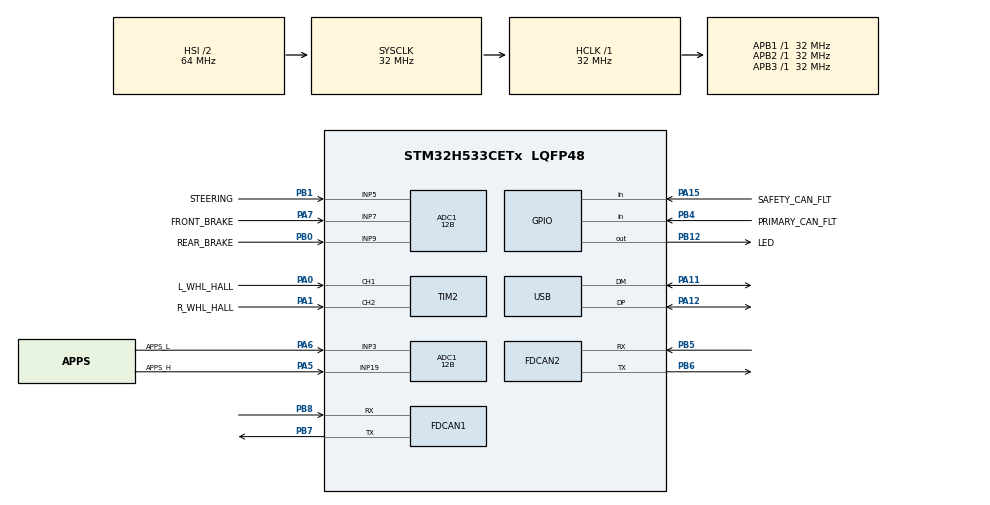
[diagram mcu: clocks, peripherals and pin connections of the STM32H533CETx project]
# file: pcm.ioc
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ADC1.Channel-1\#ChannelRegularConversion=ADC_CHANNEL_19
ADC1.Channel-2\#ChannelRegularConversion=ADC_CHANNEL_3
ADC1.Channel-3\#ChannelRegularConversion=ADC_CHANNEL_7
ADC1.Channel-4\#ChannelRegularConversion=ADC_CHANNEL_9
ADC1.Channel-5\#ChannelRegularConversion=ADC_CHANNEL_5
ADC1.DMAContinuousRequests=ENABLE
ADC1.MonitoredBy-1\#ChannelRegularConversion=__NULL
ADC1.MonitoredBy-2\#ChannelRegularConversion=__NULL
ADC1.MonitoredBy-3\#ChannelRegularConversion=__NULL
ADC1.MonitoredBy-4\#ChannelRegularConversion=__NULL
ADC1.MonitoredBy-5\#ChannelRegularConversion=__NULL
ADC1.NbrOfConversion=5
ADC1.NbrOfConversionFlag=1
ADC1.OffsetNumber-1\#ChannelRegularConversion=ADC_OFFSET_NONE
ADC1.OffsetNumber-2\#ChannelRegularConversion=ADC_OFFSET_NONE
ADC1.OffsetNumber-3\#ChannelRegularConversion=ADC_OFFSET_NONE
ADC1.OffsetNumber-4\#ChannelRegularConversion=ADC_OFFSET_NONE
ADC1.OffsetNumber-5\#ChannelRegularConversion=ADC_OFFSET_NONE
ADC1.Overrun=ADC_OVR_DATA_OVERWRITTEN
ADC1.Rank-1\#ChannelRegularConversion=1
ADC1.Rank-2\#ChannelRegularConversion=2
ADC1.Rank-3\#ChannelRegularConversion=3
ADC1.Rank-4\#ChannelRegularConversion=4
ADC1.Rank-5\#ChannelRegularConversion=5
ADC1.Resolution=ADC_RESOLUTION_12B
ADC1.SamplingTime-1\#ChannelRegularConversion=ADC_SAMPLETIME_47CYCLES_5
ADC1.SamplingTime-2\#ChannelRegularConversion=ADC_SAMPLETIME_47CYCLES_5
ADC1.SamplingTime-3\#ChannelRegularConversion=ADC_SAMPLETIME_47CYCLES_5
ADC1.SamplingTime-4\#ChannelRegularConversion=ADC_SAMPLETIME_47CYCLES_5
ADC1.SamplingTime-5\#ChannelRegularConversion=ADC_SAMPLETIME_47CYCLES_5
ADC1.master=1
BOOTPATH.BootPathName=LEGACY
BOOTPATH.UserSelectedBootPath=LEGACY
CORTEX_M33_NS.Number-Cortex_Memory_Protection_Unit_Region0_OTP_RO_AREAS_Settings=MPU_REGION_NUMBER0
CORTEX_M33_NS.default_mode_Activation=1
CORTEX_M33_NS.userName=CORTEX_M33
FDCAN1.CalculateBaudRateNominal=500000
FDCAN1.CalculateTimeBitNominal=2000
FDCAN1.CalculateTimeQuantumNominal=666.6666666666666
FDCAN2.CalculateBaudRateNominal=500000
FDCAN2.CalculateTimeBitNominal=2000
FDCAN2.CalculateTimeQuantumNominal=666.6666666666666
GPDMA1.DESTDATAWIDTH_GPDMACH0=DMA_DEST_DATAWIDTH_HALFWORD
GPDMA1.DESTINC_GPDMACH0=DMA_DINC_INCREMENTED
GPDMA1.IPHANDLE_GPDMACH0-SIMPLEREQUEST_GPDMACH0=__NULL
GPDMA1.REQUEST_GPDMACH0=GPDMA1_REQUEST_ADC1
GPDMA1.SRCDATAWIDTH_GPDMACH0=DMA_SRC_DATAWIDTH_HALFWORD
Mcu.Family=STM32H5
Mcu.Name=STM32H533CETx
Mcu.Package=LQFP48
NVIC.GPDMA1_Channel0_IRQn=true\:0\:0\:false\:false\:true\:true\:false\:true\:true
NVIC.PriorityGroup=NVIC_PRIORITYGROUP_4
NVIC.TIM7_IRQn=true\:15\:0\:false\:false\:true\:false\:false\:true\:true
NVIC.TimeBase=TIM7_IRQn
NVIC.TimeBaseIP=TIM7
NVIC.USB_DRD_FS_IRQn=true\:0\:0\:false\:false\:true\:false\:true\:true\:true
PA0.GPIO_Label=L_WHL_HALL
PA0.Signal=S_TIM2_CH1
PA1.GPIO_Label=R_WHL_HALL
PA1.Signal=S_TIM2_CH2
PA11.Mode=Device
PA11.Signal=USB_DM
PA12.Mode=Device
PA12.Signal=USB_DP
PA13(JTMS/SWDIO).Mode=Trace_Asynchronous_SW
PA13(JTMS/SWDIO).Signal=DEBUG_JTMS-SWDIO
PA14(JTCK/SWCLK).Mode=Trace_Asynchronous_SW
PA14(JTCK/SWCLK).Signal=DEBUG_JTCK-SWCLK
PA15(JTDI).GPIO_Label=SAFETY_CAN_FLT
PA15(JTDI).Signal=GPIO_Input
PA5.GPIO_Label=APPS_H
PA5.Signal=ADCx_INP19
PA6.GPIO_Label=APPS_L
PA6.Signal=ADCx_INP3
PA7.GPIO_Label=FRONT_BRAKE
PA7.Signal=ADCx_INP7
PB0.GPIO_Label=REAR_BRAKE
PB0.Signal=ADCx_INP9
PB1.GPIO_Label=STEERING
PB1.Signal=ADCx_INP5
PB12.GPIO_Label=LED
PB12.Signal=GPIO_Output
PB3(JTDO/TRACESWO).Mode=Trace_Asynchronous_SW
PB3(JTDO/TRACESWO).Signal=DEBUG_JTDO-SWO
PB4(NJTRST).GPIO_Label=PRIMARY_CAN_FLT
PB4(NJTRST).Signal=GPIO_Input
PB5.Mode=FDCAN_Activate
PB5.Signal=FDCAN2_RX
PB6.Mode=FDCAN_Activate
PB6.Signal=FDCAN2_TX
PB7.Mode=FDCAN_Activate
PB7.Signal=FDCAN1_TX
PB8.Mode=FDCAN_Activate
PB8.Signal=FDCAN1_RX
PC14-OSC32_IN(OSC32_IN).Mode=LSE-External-Oscillator
PC14-OSC32_IN(OSC32_IN).Signal=RCC_OSC32_IN
PC15-OSC32_OUT(OSC32_OUT).Mode=LSE-External-Oscillator
PC15-OSC32_OUT(OSC32_OUT).Signal=RCC_OSC32_OUT
PH0-OSC_IN(PH0).Mode=HSE-External-Oscillator
PH0-OSC_IN(PH0).Signal=RCC_OSC_IN
PH1-OSC_OUT(PH1).Mode=HSE-External-Oscillator
PH1-OSC_OUT(PH1).Signal=RCC_OSC_OUT
ProjectManager.HeapSize=0x200
ProjectManager.StackSize=0x400
ProjectManager.TargetToolchain=CMake
RCC.ADCFreq_Value=32000000
RCC.AHBFreq_Value=32000000
RCC.APB1Freq_Value=32000000
RCC.APB1TimFreq_Value=32000000
RCC.APB2Freq_Value=32000000
RCC.APB2TimFreq_Value=32000000
RCC.APB3Freq_Value=32000000
RCC.CSI_VALUE=4000000
RCC.CortexFreq_Value=32000000
RCC.EPOD_VALUE=4000000
RCC.HCLKFreq_Value=32000000
RCC.HSE_VALUE=24000000
RCC.HSI48_VALUE=48000000
RCC.HSI_VALUE=64000000
RCC.LSIRC_VALUE=32000
RCC.SYSCLKFreq_VALUE=32000000
RCC.USBFreq_Value=48000000
RCC.VCOOutputFreq_Value=516000000
SH.ADCx_INP19.0=ADC1_INP19,IN19-Single-Ended
SH.ADCx_INP3.0=ADC1_INP3,IN3-Single-Ended
SH.ADCx_INP5.0=ADC1_INP5,IN5-Single-Ended
SH.ADCx_INP7.0=ADC1_INP7,IN7-Single-Ended
SH.ADCx_INP9.0=ADC1_INP9,IN9-Single-Ended
SH.S_TIM2_CH1.0=TIM2_CH1,Input_Capture1_from_TI1
SH.S_TIM2_CH2.0=TIM2_CH2,Input_Capture2_from_TI2
THREADX.TX_APP_GENERATE_INIT_CODE=true
THREADX.TX_APP_MEM_POOL_SIZE=65536
TIM2.Channel-Input_Capture1_from_TI1=TIM_CHANNEL_1
TIM2.Channel-Input_Capture2_from_TI2=TIM_CHANNEL_2
USB.VirtualMode=Device_Only
USBX.BSP.number=1
USBX.Core_System=1
USBX.USBD_CDCACM_EPIN_ADDR=2
USBX.USBD_CDCACM_EPOUT_ADDR=3
USBX.USBD_MANUFACTURER_STRING=IIT Motorsports
USBX.USBD_PRODUCT_STRING=Propulsion Control Module (PCM)
USBX.USBX_SYS_SIZE=10240
USBX.UX_APP_MEM_POOL_SIZE=20480
USBX.UX_DEVICE_CDC_ACM=1
USBX.UX_DEVICE_ENABLED_FS=1
USBX.UX_Device_Controller=1
USBX.UX_Device_CoreStack=1
USBX.UX_enabled_FS=1
USBX0.BSP.STBoard=false
USBX0.BSP.api=Unknown
USBX0.BSP.condition=\!DIE47A
USBX0.BSP.instance=USB
USBX0.BSP.ip=USB
USBX0.BSP.mode=Device_Only
USBX0.BSP.name=USB_Device
USBX0.BSP.solution=USB
VP_BOOTPATH_VS_BOOTPATH.Mode=BP_Activate
VP_CORTEX_M33_NS_VS_Hclk.Mode=Hclk_Mode
VP_GPDMA1_VS_GPDMACH0.Mode=SIMPLEREQUEST_GPDMACH0
VP_ICACHE_VS_ICACHE.Mode=DirectMappedCache
VP_MEMORYMAP_VS_MEMORYMAP.Mode=CurAppReg
VP_PWR_VS_LPOM.Mode=PowerOptimisation
VP_PWR_VS_SECSignals.Mode=Security/Privilege
VP_SYS_VS_tim7.Mode=TIM7
VP_THREADX_VS_RTOSJjThreadXJjCoreJjDefault.Mode=Core_Default
VP_USBX_Core_System.Mode=Core_System
VP_USBX_UX\ Device\ CDC\ ACM\ Class_FS.Mode=UX_Device_class_CDC_ACM_FS_HS
VP_USBX_UX\ Device\ Controller_FS.Mode=UX_Device_Controller_FS
VP_USBX_UX\ Device\ CoreStack_FS.Mode=UX_Device_CoreStack
board=custom

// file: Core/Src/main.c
/* USER CODE BEGIN Header */
/**
  ******************************************************************************
  * @file           : main.c
  * @brief          : Main program body
  ******************************************************************************
  * @attention
  *
  * Copyright (c) 2026 STMicroelectronics.
  * All rights reserved.
  *
  * This software is licensed under terms that can be found in the LICENSE file
  * in the root directory of this software component.
  * If no LICENSE file comes with this software, it is provided AS-IS.
  *
  ******************************************************************************
  */
/* USER CODE END Header */
#include "app_threadx.h"
#include "main.h"

/* USER CODE BEGIN Includes */
#include "pcm.h"
/* USER CODE END Includes */

ADC_HandleTypeDef hadc1;
DMA_HandleTypeDef handle_GPDMA1_Channel0;

FDCAN_HandleTypeDef hfdcan1;
FDCAN_HandleTypeDef hfdcan2;

TIM_HandleTypeDef htim2;

PCD_HandleTypeDef hpcd_USB_DRD_FS;

void SystemClock_Config(void);
static void MPU_Config(void);
static void MX_GPIO_Init(void);
static void MX_GPDMA1_Init(void);
static void MX_ADC1_Init(void);
static void MX_FDCAN1_Init(void);
static void MX_FDCAN2_Init(void);
static void MX_ICACHE_Init(void);
static void MX_TIM2_Init(void);

int main(void)
{

  /* MCU Configuration--------------------------------------------------------*/

  /* MPU Configuration--------------------------------------------------------*/
  MPU_Config();

  /* Reset of all peripherals, Initializes the Flash interface and the Systick. */
  HAL_Init();

  /* Configure the system clock */
  SystemClock_Config();

  /* Initialize all configured peripherals */
  MX_GPIO_Init();
  MX_GPDMA1_Init();
  MX_ADC1_Init();
  MX_FDCAN1_Init();
  MX_FDCAN2_Init();
  MX_ICACHE_Init();
  MX_TIM2_Init();
  /* USER CODE BEGIN 2 */
  pcm_init();
  /* USER CODE END 2 */

  MX_ThreadX_Init();

  /* We should never get here as control is now taken by the scheduler */

  /* Infinite loop */
  while (1)
  {

  }
}

void SystemClock_Config(void)
{
  RCC_OscInitTypeDef RCC_OscInitStruct = {0};
  RCC_ClkInitTypeDef RCC_ClkInitStruct = {0};

  /** Configure the main internal regulator output voltage
  */
  __HAL_PWR_VOLTAGESCALING_CONFIG(PWR_REGULATOR_VOLTAGE_SCALE3);

  while(!__HAL_PWR_GET_FLAG(PWR_FLAG_VOSRDY)) {}

  /** Initializes the RCC Oscillators according to the specified parameters
  * in the RCC_OscInitTypeDef structure.
  */
  RCC_OscInitStruct.OscillatorType = RCC_OSCILLATORTYPE_HSI48|RCC_OSCILLATORTYPE_HSI
                              |RCC_OSCILLATORTYPE_HSE;
  RCC_OscInitStruct.HSEState = RCC_HSE_ON;
  RCC_OscInitStruct.HSIState = RCC_HSI_ON;
  RCC_OscInitStruct.HSIDiv = RCC_HSI_DIV2;
  RCC_OscInitStruct.HSICalibrationValue = RCC_HSICALIBRATION_DEFAULT;
  RCC_OscInitStruct.HSI48State = RCC_HSI48_ON;
  RCC_OscInitStruct.PLL.PLLState = RCC_PLL_NONE;
  if (HAL_RCC_OscConfig(&RCC_OscInitStruct) != HAL_OK)
  {
    Error_Handler();
  }

  /** Initializes the CPU, AHB and APB buses clocks
  */
  RCC_ClkInitStruct.ClockType = RCC_CLOCKTYPE_HCLK|RCC_CLOCKTYPE_SYSCLK
                              |RCC_CLOCKTYPE_PCLK1|RCC_CLOCKTYPE_PCLK2
                              |RCC_CLOCKTYPE_PCLK3;
  RCC_ClkInitStruct.SYSCLKSource = RCC_SYSCLKSOURCE_HSI;
  RCC_ClkInitStruct.AHBCLKDivider = RCC_SYSCLK_DIV1;
  RCC_ClkInitStruct.APB1CLKDivider = RCC_HCLK_DIV1;
  RCC_ClkInitStruct.APB2CLKDivider = RCC_HCLK_DIV1;
  RCC_ClkInitStruct.APB3CLKDivider = RCC_HCLK_DIV1;

  if (HAL_RCC_ClockConfig(&RCC_ClkInitStruct, FLASH_LATENCY_1) != HAL_OK)
  {
    Error_Handler();
  }

  /** Configure the programming delay
  */
  __HAL_FLASH_SET_PROGRAM_DELAY(FLASH_PROGRAMMING_DELAY_0);
}

static void MX_ADC1_Init(void)
{

  ADC_ChannelConfTypeDef sConfig = {0};

  /** Common config
  */
  hadc1.Instance = ADC1;
  hadc1.Init.ClockPrescaler = ADC_CLOCK_ASYNC_DIV1;
  hadc1.Init.Resolution = ADC_RESOLUTION_12B;
  hadc1.Init.DataAlign = ADC_DATAALIGN_RIGHT;
  hadc1.Init.ScanConvMode = ADC_SCAN_ENABLE;
  hadc1.Init.EOCSelection = ADC_EOC_SINGLE_CONV;
  hadc1.Init.LowPowerAutoWait = DISABLE;
  hadc1.Init.ContinuousConvMode = DISABLE;
  hadc1.Init.NbrOfConversion = 5;
  hadc1.Init.DiscontinuousConvMode = DISABLE;
  hadc1.Init.ExternalTrigConv = ADC_SOFTWARE_START;
  hadc1.Init.ExternalTrigConvEdge = ADC_EXTERNALTRIGCONVEDGE_NONE;
  hadc1.Init.DMAContinuousRequests = ENABLE;
  hadc1.Init.SamplingMode = ADC_SAMPLING_MODE_NORMAL;
  hadc1.Init.Overrun = ADC_OVR_DATA_OVERWRITTEN;
  hadc1.Init.OversamplingMode = DISABLE;
  if (HAL_ADC_Init(&hadc1) != HAL_OK)
  {
    Error_Handler();
  }

  /** Configure Regular Channel
  */
  sConfig.Channel = ADC_CHANNEL_19;
  sConfig.Rank = ADC_REGULAR_RANK_1;
  sConfig.SamplingTime = ADC_SAMPLETIME_47CYCLES_5;
  sConfig.SingleDiff = ADC_SINGLE_ENDED;
  sConfig.OffsetNumber = ADC_OFFSET_NONE;
  sConfig.Offset = 0;
  if (HAL_ADC_ConfigChannel(&hadc1, &sConfig) != HAL_OK)
  {
    Error_Handler();
  }

  /** Configure Regular Channel
  */
  sConfig.Channel = ADC_CHANNEL_3;
  sConfig.Rank = ADC_REGULAR_RANK_2;
  if (HAL_ADC_ConfigChannel(&hadc1, &sConfig) != HAL_OK)
  {
    Error_Handler();
  }

  /** Configure Regular Channel
  */
  sConfig.Channel = ADC_CHANNEL_7;
  sConfig.Rank = ADC_REGULAR_RANK_3;
  if (HAL_ADC_ConfigChannel(&hadc1, &sConfig) != HAL_OK)
  {
    Error_Handler();
  }

  /** Configure Regular Channel
  */
  sConfig.Channel = ADC_CHANNEL_9;
  sConfig.Rank = ADC_REGULAR_RANK_4;
  if (HAL_ADC_ConfigChannel(&hadc1, &sConfig) != HAL_OK)
  {
    Error_Handler();
  }

  /** Configure Regular Channel
  */
  sConfig.Channel = ADC_CHANNEL_5;
  sConfig.Rank = ADC_REGULAR_RANK_5;
  if (HAL_ADC_ConfigChannel(&hadc1, &sConfig) != HAL_OK)
  {
    Error_Handler();
  }

}

static void MX_FDCAN1_Init(void)
{

  hfdcan1.Instance = FDCAN1;
  hfdcan1.Init.ClockDivider = FDCAN_CLOCK_DIV1;
  hfdcan1.Init.FrameFormat = FDCAN_FRAME_CLASSIC;
  hfdcan1.Init.Mode = FDCAN_MODE_NORMAL;
  hfdcan1.Init.AutoRetransmission = DISABLE;
  hfdcan1.Init.TransmitPause = DISABLE;
  hfdcan1.Init.ProtocolException = DISABLE;
  hfdcan1.Init.NominalPrescaler = 16;
  hfdcan1.Init.NominalSyncJumpWidth = 1;
  hfdcan1.Init.NominalTimeSeg1 = 1;
  hfdcan1.Init.NominalTimeSeg2 = 1;
  hfdcan1.Init.DataPrescaler = 1;
  hfdcan1.Init.DataSyncJumpWidth = 1;
  hfdcan1.Init.DataTimeSeg1 = 1;
  hfdcan1.Init.DataTimeSeg2 = 1;
  hfdcan1.Init.StdFiltersNbr = 1;
  hfdcan1.Init.ExtFiltersNbr = 0;
  hfdcan1.Init.TxFifoQueueMode = FDCAN_TX_FIFO_OPERATION;
  if (HAL_FDCAN_Init(&hfdcan1) != HAL_OK)
  {
    Error_Handler();
  }

}

static void MX_FDCAN2_Init(void)
{

  hfdcan2.Instance = FDCAN2;
  hfdcan2.Init.ClockDivider = FDCAN_CLOCK_DIV1;
  hfdcan2.Init.FrameFormat = FDCAN_FRAME_CLASSIC;
  hfdcan2.Init.Mode = FDCAN_MODE_NORMAL;
  hfdcan2.Init.AutoRetransmission = DISABLE;
  hfdcan2.Init.TransmitPause = DISABLE;
  hfdcan2.Init.ProtocolException = DISABLE;
  hfdcan2.Init.NominalPrescaler = 16;
  hfdcan2.Init.NominalSyncJumpWidth = 1;
  hfdcan2.Init.NominalTimeSeg1 = 1;
  hfdcan2.Init.NominalTimeSeg2 = 1;
  hfdcan2.Init.DataPrescaler = 1;
  hfdcan2.Init.DataSyncJumpWidth = 1;
  hfdcan2.Init.DataTimeSeg1 = 1;
  hfdcan2.Init.DataTimeSeg2 = 1;
  hfdcan2.Init.StdFiltersNbr = 0;
  hfdcan2.Init.ExtFiltersNbr = 0;
  hfdcan2.Init.TxFifoQueueMode = FDCAN_TX_FIFO_OPERATION;
  if (HAL_FDCAN_Init(&hfdcan2) != HAL_OK)
  {
    Error_Handler();
  }

}

static void MX_GPDMA1_Init(void)
{

  /* Peripheral clock enable */
  __HAL_RCC_GPDMA1_CLK_ENABLE();

  /* GPDMA1 interrupt Init */
    HAL_NVIC_SetPriority(GPDMA1_Channel0_IRQn, 0, 0);
    HAL_NVIC_EnableIRQ(GPDMA1_Channel0_IRQn);

}

static void MX_ICACHE_Init(void)
{

  /** Enable instruction cache in 1-way (direct mapped cache)
  */
  if (HAL_ICACHE_ConfigAssociativityMode(ICACHE_1WAY) != HAL_OK)
  {
    Error_Handler();
  }
  if (HAL_ICACHE_Enable() != HAL_OK)
  {
    Error_Handler();
  }

}

static void MX_TIM2_Init(void)
{

  TIM_MasterConfigTypeDef sMasterConfig = {0};
  TIM_IC_InitTypeDef sConfigIC = {0};

  htim2.Instance = TIM2;
  htim2.Init.Prescaler = 0;
  htim2.Init.CounterMode = TIM_COUNTERMODE_UP;
  htim2.Init.Period = 4294967295;
  htim2.Init.ClockDivision = TIM_CLOCKDIVISION_DIV1;
  htim2.Init.AutoReloadPreload = TIM_AUTORELOAD_PRELOAD_DISABLE;
  if (HAL_TIM_IC_Init(&htim2) != HAL_OK)
  {
    Error_Handler();
  }
  sMasterConfig.MasterOutputTrigger = TIM_TRGO_RESET;
  sMasterConfig.MasterSlaveMode = TIM_MASTERSLAVEMODE_DISABLE;
  if (HAL_TIMEx_MasterConfigSynchronization(&htim2, &sMasterConfig) != HAL_OK)
  {
    Error_Handler();
  }
  sConfigIC.ICPolarity = TIM_INPUTCHANNELPOLARITY_RISING;
  sConfigIC.ICSelection = TIM_ICSELECTION_DIRECTTI;
  sConfigIC.ICPrescaler = TIM_ICPSC_DIV1;
  sConfigIC.ICFilter = 0;
  if (HAL_TIM_IC_ConfigChannel(&htim2, &sConfigIC, TIM_CHANNEL_1) != HAL_OK)
  {
    Error_Handler();
  }
  if (HAL_TIM_IC_ConfigChannel(&htim2, &sConfigIC, TIM_CHANNEL_2) != HAL_OK)
  {
    Error_Handler();
  }

}

void MX_USB_PCD_Init(void)
{

  hpcd_USB_DRD_FS.Instance = USB_DRD_FS;
  hpcd_USB_DRD_FS.Init.dev_endpoints = 8;
  hpcd_USB_DRD_FS.Init.speed = USBD_FS_SPEED;
  hpcd_USB_DRD_FS.Init.phy_itface = PCD_PHY_EMBEDDED;
  hpcd_USB_DRD_FS.Init.Sof_enable = DISABLE;
  hpcd_USB_DRD_FS.Init.low_power_enable = DISABLE;
  hpcd_USB_DRD_FS.Init.lpm_enable = DISABLE;
  hpcd_USB_DRD_FS.Init.battery_charging_enable = DISABLE;
  hpcd_USB_DRD_FS.Init.vbus_sensing_enable = DISABLE;
  hpcd_USB_DRD_FS.Init.bulk_doublebuffer_enable = DISABLE;
  hpcd_USB_DRD_FS.Init.iso_singlebuffer_enable = DISABLE;
  if (HAL_PCD_Init(&hpcd_USB_DRD_FS) != HAL_OK)
  {
    Error_Handler();
  }

}

static void MX_GPIO_Init(void)
{
  GPIO_InitTypeDef GPIO_InitStruct = {0};

  /* GPIO Ports Clock Enable */
  __HAL_RCC_GPIOC_CLK_ENABLE();
  __HAL_RCC_GPIOH_CLK_ENABLE();
  __HAL_RCC_GPIOA_CLK_ENABLE();
  __HAL_RCC_GPIOB_CLK_ENABLE();

  /*Configure GPIO pin Output Level */
  HAL_GPIO_WritePin(LED_GPIO_Port, LED_Pin, GPIO_PIN_RESET);

  /*Configure GPIO pin : LED_Pin */
  GPIO_InitStruct.Pin = LED_Pin;
  GPIO_InitStruct.Mode = GPIO_MODE_OUTPUT_PP;
  GPIO_InitStruct.Pull = GPIO_NOPULL;
  GPIO_InitStruct.Speed = GPIO_SPEED_FREQ_LOW;
  HAL_GPIO_Init(LED_GPIO_Port, &GPIO_InitStruct);

  /*Configure GPIO pin : SAFETY_CAN_FLT_Pin */
  GPIO_InitStruct.Pin = SAFETY_CAN_FLT_Pin;
  GPIO_InitStruct.Mode = GPIO_MODE_INPUT;
  GPIO_InitStruct.Pull = GPIO_NOPULL;
  HAL_GPIO_Init(SAFETY_CAN_FLT_GPIO_Port, &GPIO_InitStruct);

  /*Configure GPIO pin : PRIMARY_CAN_FLT_Pin */
  GPIO_InitStruct.Pin = PRIMARY_CAN_FLT_Pin;
  GPIO_InitStruct.Mode = GPIO_MODE_INPUT;
  GPIO_InitStruct.Pull = GPIO_NOPULL;
  HAL_GPIO_Init(PRIMARY_CAN_FLT_GPIO_Port, &GPIO_InitStruct);

}

 /* MPU Configuration */

void MPU_Config(void)
{
  MPU_Region_InitTypeDef MPU_InitStruct = {0};
  MPU_Attributes_InitTypeDef MPU_AttributesInit = {0};

  /* Disables the MPU */
  HAL_MPU_Disable();

  /** Initializes and configures the Region 0 and the memory to be protected
  */
  MPU_InitStruct.Enable = MPU_REGION_ENABLE;
  MPU_InitStruct.Number = MPU_REGION_NUMBER0;
  MPU_InitStruct.BaseAddress = 0x08FFF000;
  MPU_InitStruct.LimitAddress = 0x08FFFFFF;
  MPU_InitStruct.AttributesIndex = MPU_ATTRIBUTES_NUMBER0;
  MPU_InitStruct.AccessPermission = MPU_REGION_ALL_RO;
  MPU_InitStruct.DisableExec = MPU_INSTRUCTION_ACCESS_DISABLE;
  MPU_InitStruct.IsShareable = MPU_ACCESS_NOT_SHAREABLE;

  HAL_MPU_ConfigRegion(&MPU_InitStruct);

  /** Initializes and configures the Attribute 0 and the memory to be protected
  */
  MPU_AttributesInit.Number = MPU_ATTRIBUTES_NUMBER0;
  MPU_AttributesInit.Attributes = INNER_OUTER(MPU_NOT_CACHEABLE);

  HAL_MPU_ConfigMemoryAttributes(&MPU_AttributesInit);
  /* Enables the MPU */
  HAL_MPU_Enable(MPU_PRIVILEGED_DEFAULT);

}

void HAL_TIM_PeriodElapsedCallback(TIM_HandleTypeDef *htim)
{
  if (htim->Instance == TIM7)
  {
    HAL_IncTick();
  }
}

void Error_Handler(void)
{
  __disable_irq();
  while (1)
  {
  }
}
